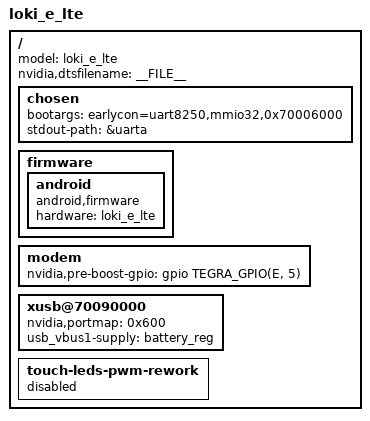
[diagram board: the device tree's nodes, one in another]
/*
 * arch/arm64/boot/dts/tegra210-loki-e-p2530-0031-e00-00.dts
 *
 * Copyright (c) 2014-2015, NVIDIA CORPORATION.  All rights reserved.
 *
 * This program is free software; you can redistribute it and/or modify
 * it under the terms of the GNU General Public License as published by
 * the Free Software Foundation; version 2 of the License.
 *
 * This program is distributed in the hope that it will be useful, but WITHOUT
 * ANY WARRANTY; without even the implied warranty of MERCHANTABILITY or
 * FITNESS FOR A PARTICULAR PURPOSE.  See the GNU General Public License for
 * more details.
 *
 * You should have received a copy of the GNU General Public License along
 * with this program; if not, write to the Free Software Foundation, Inc.,
 * 51 Franklin Street, Fifth Floor, Boston, MA  02110-1301, USA.
 *
 */

#include "tegra210-loki-e-p2530-0030-e00-00.dts"
#include "tegra210-platforms/tegra210-modem-common.dtsi"

/ {
	model = "loki_e_lte";
	nvidia,dtsfilename = __FILE__;

	chosen {
		bootargs = "earlycon=uart8250,mmio32,0x70006000";
		stdout-path = &uarta;
	};

	firmware {
		android {
			compatible = "android,firmware";
			hardware = "loki_e_lte";
		};
	};

	modem {
		/* pre boost regulator gpio */
		nvidia,pre-boost-gpio = <&gpio TEGRA_GPIO(E, 5) GPIO_ACTIVE_HIGH>;
	};

	xusb@70090000 {
		/* enable UTMI pad 1 */
		nvidia,portmap = <0x600>;
		usb_vbus1-supply = <&battery_reg>;
	};

	touch-leds-pwm-rework {
		status = "disabled";
	};
};
